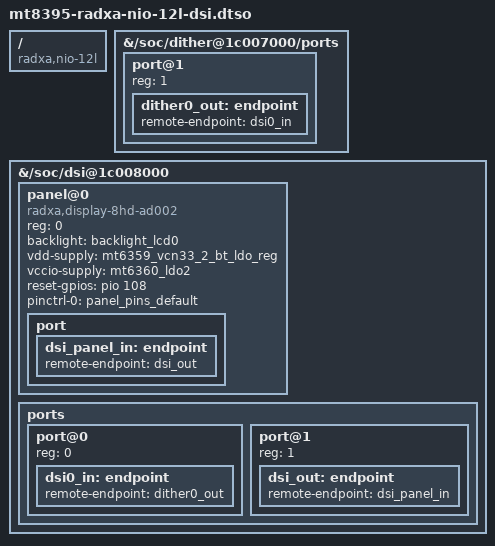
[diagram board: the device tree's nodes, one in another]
// SPDX-License-Identifier: (GPL-2.0 OR MIT)
/*
 * Copyright (C) 2024 Collabora Ltd.
 *                    AngeloGioacchino Del Regno <angelogioacchino.delregno@collabora.com>
 */

/dts-v1/;
/plugin/;

#include <dt-bindings/gpio/gpio.h>

/ {
	compatible = "radxa,nio-12l", "mediatek,mt8395", "mediatek,mt8195";

	fragment@0 {
		target-path = "/soc/dither@1c007000/ports";
		__overlay__ {
			#address-cells = <1>;
			#size-cells = <0>;

			port@1 {
				reg = <1>;
				dither0_out: endpoint {
					remote-endpoint = <&dsi0_in>;
				};
			};
		};
	};

	fragment@1 {
		target-path = "/soc/dsi@1c008000";
		__overlay__ {
			status = "okay";
			#address-cells = <1>;
			#size-cells = <0>;

			panel@0 {
				compatible = "radxa,display-8hd-ad002", "jadard,jd9365da-h3";
				reg = <0>;
				backlight = <&backlight_lcd0>;
				vdd-supply = <&mt6359_vcn33_2_bt_ldo_reg>;
				vccio-supply = <&mt6360_ldo2>;
				reset-gpios = <&pio 108 GPIO_ACTIVE_HIGH>;
				pinctrl-names = "default";
				pinctrl-0 = <&panel_pins_default>;

				port {
					dsi_panel_in: endpoint {
						remote-endpoint = <&dsi_out>;
					};
				};
			};

			ports {
				#address-cells = <1>;
				#size-cells = <0>;

				port@0 {
					reg = <0>;
					dsi0_in: endpoint {
						remote-endpoint = <&dither0_out>;
					};
				};

				port@1 {
					reg = <1>;
					dsi_out: endpoint {
						remote-endpoint = <&dsi_panel_in>;
					};
				};
			};
		};
	};
};

